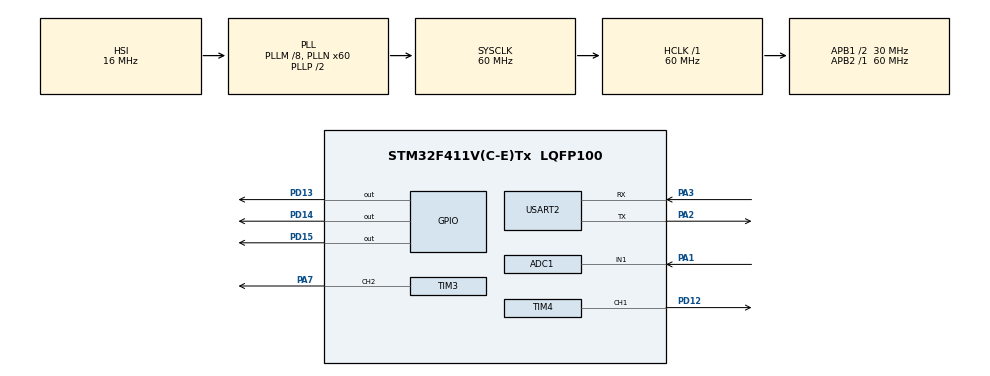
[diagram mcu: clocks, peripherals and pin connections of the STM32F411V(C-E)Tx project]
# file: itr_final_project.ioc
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ADC1.Channel-0\#ChannelRegularConversion=ADC_CHANNEL_1
ADC1.ExternalTrigConv=ADC_EXTERNALTRIGCONV_T2_TRGO
ADC1.NbrOfConversion=1
ADC1.NbrOfConversionFlag=1
ADC1.Rank-0\#ChannelRegularConversion=1
ADC1.SamplingTime-0\#ChannelRegularConversion=ADC_SAMPLETIME_480CYCLES
ADC1.master=1
Mcu.Family=STM32F4
Mcu.Name=STM32F411V(C-E)Tx
Mcu.Package=LQFP100
NVIC.ADC_IRQn=true\:0\:0\:false\:false\:true\:true\:true\:true
NVIC.PriorityGroup=NVIC_PRIORITYGROUP_4
NVIC.TIM3_IRQn=true\:0\:0\:false\:false\:true\:true\:true\:true
NVIC.USART2_IRQn=true\:0\:0\:false\:false\:true\:true\:true\:true
PA1.Signal=ADCx_IN1
PA13.Mode=Serial_Wire
PA13.Signal=SYS_JTMS-SWDIO
PA14.Mode=Serial_Wire
PA14.Signal=SYS_JTCK-SWCLK
PA2.Mode=Asynchronous
PA2.Signal=USART2_TX
PA3.Mode=Asynchronous
PA3.Signal=USART2_RX
PA7.Signal=S_TIM3_CH2
PD12.Signal=S_TIM4_CH1
PD13.Signal=GPIO_Output
PD14.Signal=GPIO_Output
PD15.Signal=GPIO_Output
PH0\ -\ OSC_IN.Mode=HSE-External-Oscillator
PH0\ -\ OSC_IN.Signal=RCC_OSC_IN
PH1\ -\ OSC_OUT.Mode=HSE-External-Oscillator
PH1\ -\ OSC_OUT.Signal=RCC_OSC_OUT
ProjectManager.HeapSize=0x200
ProjectManager.StackSize=0x400
ProjectManager.TargetToolchain=STM32CubeIDE
RCC.48MHZClocksFreq_Value=30000000
RCC.AHBFreq_Value=60000000
RCC.APB1CLKDivider=RCC_HCLK_DIV2
RCC.APB1Freq_Value=30000000
RCC.APB1TimFreq_Value=60000000
RCC.APB2Freq_Value=60000000
RCC.APB2TimFreq_Value=60000000
RCC.CortexFreq_Value=60000000
RCC.HCLKFreq_Value=60000000
RCC.HSE_VALUE=25000000
RCC.HSI_VALUE=16000000
RCC.LSE_VALUE=32768
RCC.PLLM=8
RCC.PLLN=60
RCC.SYSCLKFreq_VALUE=60000000
RCC.SYSCLKSource=RCC_SYSCLKSOURCE_PLLCLK
RCC.VCOOutputFreq_Value=120000000
SH.ADCx_IN1.0=ADC1_IN1,IN1
SH.S_TIM3_CH2.0=TIM3_CH2,PWM Generation2 CH2
SH.S_TIM4_CH1.0=TIM4_CH1,PWM Generation1 CH1
TIM2.Channel-PWM\ Generation1\ No\ Output=TIM_CHANNEL_1
TIM2.Period=119999
TIM2.TIM_MasterOutputTrigger=TIM_TRGO_UPDATE
TIM3.Channel-PWM\ Generation2\ CH2=TIM_CHANNEL_2
TIM3.Period=62499
TIM3.Prescaler=959
TIM3.Pulse-PWM\ Generation2\ CH2=31249
TIM4.Channel-PWM\ Generation1\ CH1=TIM_CHANNEL_1
TIM4.Period=999
TIM4.Prescaler=7
TIM4.Pulse-PWM\ Generation1\ CH1=499
USART2.VirtualMode=VM_ASYNC
VP_TIM2_VS_ClockSourceINT.Mode=Internal
VP_TIM2_VS_no_output1.Mode=PWM Generation1 No Output
VP_TIM3_VS_ClockSourceINT.Mode=Internal
VP_TIM4_VS_ClockSourceINT.Mode=Internal
board=custom

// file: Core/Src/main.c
/* USER CODE BEGIN Header */
/**
 ******************************************************************************
 * @file           : main.c
 * @brief          : Main program body
 ******************************************************************************
 * @attention
 *
 * Copyright (c) 2024 STMicroelectronics.
 * All rights reserved.
 *
 * This software is licensed under terms that can be found in the LICENSE file
 * in the root directory of this software component.
 * If no LICENSE file comes with this software, it is provided AS-IS.
 *
 ******************************************************************************
 */
/* USER CODE END Header */
#include "main.h"

/* USER CODE BEGIN Includes */
#include "sys_buzz.h"
#include "sys_led.h"
#include "sys_mng.h"
#include "sys_uart.h"

/* USER CODE END Includes */

ADC_HandleTypeDef hadc1;

TIM_HandleTypeDef htim2;
TIM_HandleTypeDef htim3;
TIM_HandleTypeDef htim4;

UART_HandleTypeDef huart2;

void        SystemClock_Config(void);
static void MX_GPIO_Init(void);
static void MX_TIM3_Init(void);
static void MX_TIM4_Init(void);
static void MX_ADC1_Init(void);
static void MX_TIM2_Init(void);
static void MX_USART2_UART_Init(void);

int main(void)
{

  /* MCU Configuration--------------------------------------------------------*/

  /* Reset of all peripherals, Initializes the Flash interface and the Systick. */
  HAL_Init();

  /* Configure the system clock */
  SystemClock_Config();

  /* Initialize all configured peripherals */
  MX_GPIO_Init();
  MX_TIM3_Init();
  MX_TIM4_Init();
  MX_ADC1_Init();
  MX_TIM2_Init();
  MX_USART2_UART_Init();
  /* USER CODE BEGIN 2 */
  sys_mng_init(&hadc1, &htim2, TIM_CHANNEL_1);
  sys_uart_init(&huart2);
  sys_led_init(&htim3);
  sys_buzzer_init(&htim4, GPIOD, GPIO_PIN_15);

  /* USER CODE END 2 */

  /* Infinite loop */
  /* USER CODE BEGIN WHILE */
  while (1)
  {
    sys_uart_loop();
    sys_mng_loop();
    sys_buzzer_loop();
    sys_led_loop();
    /* USER CODE END WHILE */

  }
}

void SystemClock_Config(void)
{
  RCC_OscInitTypeDef RCC_OscInitStruct = { 0 };
  RCC_ClkInitTypeDef RCC_ClkInitStruct = { 0 };

  /** Configure the main internal regulator output voltage
   */
  __HAL_RCC_PWR_CLK_ENABLE();
  __HAL_PWR_VOLTAGESCALING_CONFIG(PWR_REGULATOR_VOLTAGE_SCALE1);

  /** Initializes the RCC Oscillators according to the specified parameters
   * in the RCC_OscInitTypeDef structure.
   */
  RCC_OscInitStruct.OscillatorType      = RCC_OSCILLATORTYPE_HSI;
  RCC_OscInitStruct.HSIState            = RCC_HSI_ON;
  RCC_OscInitStruct.HSICalibrationValue = RCC_HSICALIBRATION_DEFAULT;
  RCC_OscInitStruct.PLL.PLLState        = RCC_PLL_ON;
  RCC_OscInitStruct.PLL.PLLSource       = RCC_PLLSOURCE_HSI;
  RCC_OscInitStruct.PLL.PLLM            = 8;
  RCC_OscInitStruct.PLL.PLLN            = 60;
  RCC_OscInitStruct.PLL.PLLP            = RCC_PLLP_DIV2;
  RCC_OscInitStruct.PLL.PLLQ            = 4;
  if (HAL_RCC_OscConfig(&RCC_OscInitStruct) != HAL_OK)
  {
    Error_Handler();
  }

  /** Initializes the CPU, AHB and APB buses clocks
   */
  RCC_ClkInitStruct.ClockType = RCC_CLOCKTYPE_HCLK | RCC_CLOCKTYPE_SYSCLK |
  RCC_CLOCKTYPE_PCLK1 | RCC_CLOCKTYPE_PCLK2;
  RCC_ClkInitStruct.SYSCLKSource   = RCC_SYSCLKSOURCE_PLLCLK;
  RCC_ClkInitStruct.AHBCLKDivider  = RCC_SYSCLK_DIV1;
  RCC_ClkInitStruct.APB1CLKDivider = RCC_HCLK_DIV2;
  RCC_ClkInitStruct.APB2CLKDivider = RCC_HCLK_DIV1;

  if (HAL_RCC_ClockConfig(&RCC_ClkInitStruct, FLASH_LATENCY_1) != HAL_OK)
  {
    Error_Handler();
  }
}

static void MX_ADC1_Init(void)
{

  ADC_ChannelConfTypeDef sConfig = { 0 };

  /** Configure the global features of the ADC (Clock, Resolution, Data Alignment and number of conversion)
   */
  hadc1.Instance                   = ADC1;
  hadc1.Init.ClockPrescaler        = ADC_CLOCK_SYNC_PCLK_DIV2;
  hadc1.Init.Resolution            = ADC_RESOLUTION_12B;
  hadc1.Init.ScanConvMode          = DISABLE;
  hadc1.Init.ContinuousConvMode    = DISABLE;
  hadc1.Init.DiscontinuousConvMode = DISABLE;
  hadc1.Init.ExternalTrigConvEdge  = ADC_EXTERNALTRIGCONVEDGE_RISING;
  hadc1.Init.ExternalTrigConv      = ADC_EXTERNALTRIGCONV_T2_TRGO;
  hadc1.Init.DataAlign             = ADC_DATAALIGN_RIGHT;
  hadc1.Init.NbrOfConversion       = 1;
  hadc1.Init.DMAContinuousRequests = DISABLE;
  hadc1.Init.EOCSelection          = ADC_EOC_SINGLE_CONV;
  if (HAL_ADC_Init(&hadc1) != HAL_OK)
  {
    Error_Handler();
  }

  /** Configure for the selected ADC regular channel its corresponding rank in the sequencer and its sample time.
   */
  sConfig.Channel      = ADC_CHANNEL_1;
  sConfig.Rank         = 1;
  sConfig.SamplingTime = ADC_SAMPLETIME_480CYCLES;
  if (HAL_ADC_ConfigChannel(&hadc1, &sConfig) != HAL_OK)
  {
    Error_Handler();
  }
}

static void MX_TIM2_Init(void)
{

  TIM_ClockConfigTypeDef  sClockSourceConfig = { 0 };
  TIM_MasterConfigTypeDef sMasterConfig      = { 0 };
  TIM_OC_InitTypeDef      sConfigOC          = { 0 };

  htim2.Instance               = TIM2;
  htim2.Init.Prescaler         = 0;
  htim2.Init.CounterMode       = TIM_COUNTERMODE_UP;
  htim2.Init.Period            = 119999;
  htim2.Init.ClockDivision     = TIM_CLOCKDIVISION_DIV1;
  htim2.Init.AutoReloadPreload = TIM_AUTORELOAD_PRELOAD_DISABLE;
  if (HAL_TIM_Base_Init(&htim2) != HAL_OK)
  {
    Error_Handler();
  }
  sClockSourceConfig.ClockSource = TIM_CLOCKSOURCE_INTERNAL;
  if (HAL_TIM_ConfigClockSource(&htim2, &sClockSourceConfig) != HAL_OK)
  {
    Error_Handler();
  }
  if (HAL_TIM_PWM_Init(&htim2) != HAL_OK)
  {
    Error_Handler();
  }
  sMasterConfig.MasterOutputTrigger = TIM_TRGO_UPDATE;
  sMasterConfig.MasterSlaveMode     = TIM_MASTERSLAVEMODE_DISABLE;
  if (HAL_TIMEx_MasterConfigSynchronization(&htim2, &sMasterConfig) != HAL_OK)
  {
    Error_Handler();
  }
  sConfigOC.OCMode     = TIM_OCMODE_PWM1;
  sConfigOC.Pulse      = 0;
  sConfigOC.OCPolarity = TIM_OCPOLARITY_HIGH;
  sConfigOC.OCFastMode = TIM_OCFAST_DISABLE;
  if (HAL_TIM_PWM_ConfigChannel(&htim2, &sConfigOC, TIM_CHANNEL_1) != HAL_OK)
  {
    Error_Handler();
  }
}

static void MX_TIM3_Init(void)
{

  TIM_ClockConfigTypeDef  sClockSourceConfig = { 0 };
  TIM_MasterConfigTypeDef sMasterConfig      = { 0 };
  TIM_OC_InitTypeDef      sConfigOC          = { 0 };

  htim3.Instance               = TIM3;
  htim3.Init.Prescaler         = 959;
  htim3.Init.CounterMode       = TIM_COUNTERMODE_UP;
  htim3.Init.Period            = 62499;
  htim3.Init.ClockDivision     = TIM_CLOCKDIVISION_DIV1;
  htim3.Init.AutoReloadPreload = TIM_AUTORELOAD_PRELOAD_DISABLE;
  if (HAL_TIM_Base_Init(&htim3) != HAL_OK)
  {
    Error_Handler();
  }
  sClockSourceConfig.ClockSource = TIM_CLOCKSOURCE_INTERNAL;
  if (HAL_TIM_ConfigClockSource(&htim3, &sClockSourceConfig) != HAL_OK)
  {
    Error_Handler();
  }
  if (HAL_TIM_PWM_Init(&htim3) != HAL_OK)
  {
    Error_Handler();
  }
  sMasterConfig.MasterOutputTrigger = TIM_TRGO_RESET;
  sMasterConfig.MasterSlaveMode     = TIM_MASTERSLAVEMODE_DISABLE;
  if (HAL_TIMEx_MasterConfigSynchronization(&htim3, &sMasterConfig) != HAL_OK)
  {
    Error_Handler();
  }
  sConfigOC.OCMode     = TIM_OCMODE_PWM1;
  sConfigOC.Pulse      = 31249;
  sConfigOC.OCPolarity = TIM_OCPOLARITY_HIGH;
  sConfigOC.OCFastMode = TIM_OCFAST_DISABLE;
  if (HAL_TIM_PWM_ConfigChannel(&htim3, &sConfigOC, TIM_CHANNEL_2) != HAL_OK)
  {
    Error_Handler();
  }
  HAL_TIM_MspPostInit(&htim3);
}

static void MX_TIM4_Init(void)
{

  TIM_ClockConfigTypeDef  sClockSourceConfig = { 0 };
  TIM_MasterConfigTypeDef sMasterConfig      = { 0 };
  TIM_OC_InitTypeDef      sConfigOC          = { 0 };

  htim4.Instance               = TIM4;
  htim4.Init.Prescaler         = 7;
  htim4.Init.CounterMode       = TIM_COUNTERMODE_UP;
  htim4.Init.Period            = 999;
  htim4.Init.ClockDivision     = TIM_CLOCKDIVISION_DIV1;
  htim4.Init.AutoReloadPreload = TIM_AUTORELOAD_PRELOAD_DISABLE;
  if (HAL_TIM_Base_Init(&htim4) != HAL_OK)
  {
    Error_Handler();
  }
  sClockSourceConfig.ClockSource = TIM_CLOCKSOURCE_INTERNAL;
  if (HAL_TIM_ConfigClockSource(&htim4, &sClockSourceConfig) != HAL_OK)
  {
    Error_Handler();
  }
  if (HAL_TIM_PWM_Init(&htim4) != HAL_OK)
  {
    Error_Handler();
  }
  sMasterConfig.MasterOutputTrigger = TIM_TRGO_RESET;
  sMasterConfig.MasterSlaveMode     = TIM_MASTERSLAVEMODE_DISABLE;
  if (HAL_TIMEx_MasterConfigSynchronization(&htim4, &sMasterConfig) != HAL_OK)
  {
    Error_Handler();
  }
  sConfigOC.OCMode     = TIM_OCMODE_PWM1;
  sConfigOC.Pulse      = 499;
  sConfigOC.OCPolarity = TIM_OCPOLARITY_HIGH;
  sConfigOC.OCFastMode = TIM_OCFAST_DISABLE;
  if (HAL_TIM_PWM_ConfigChannel(&htim4, &sConfigOC, TIM_CHANNEL_1) != HAL_OK)
  {
    Error_Handler();
  }
  HAL_TIM_MspPostInit(&htim4);
}

static void MX_USART2_UART_Init(void)
{

  huart2.Instance          = USART2;
  huart2.Init.BaudRate     = 115200;
  huart2.Init.WordLength   = UART_WORDLENGTH_8B;
  huart2.Init.StopBits     = UART_STOPBITS_1;
  huart2.Init.Parity       = UART_PARITY_NONE;
  huart2.Init.Mode         = UART_MODE_TX_RX;
  huart2.Init.HwFlowCtl    = UART_HWCONTROL_NONE;
  huart2.Init.OverSampling = UART_OVERSAMPLING_16;
  if (HAL_UART_Init(&huart2) != HAL_OK)
  {
    Error_Handler();
  }
}

static void MX_GPIO_Init(void)
{
  GPIO_InitTypeDef GPIO_InitStruct = { 0 };

  /* GPIO Ports Clock Enable */
  __HAL_RCC_GPIOH_CLK_ENABLE();
  __HAL_RCC_GPIOA_CLK_ENABLE();
  __HAL_RCC_GPIOD_CLK_ENABLE();

  /*Configure GPIO pin Output Level */
  HAL_GPIO_WritePin(GPIOD, GPIO_PIN_13 | GPIO_PIN_14 | GPIO_PIN_15, GPIO_PIN_RESET);

  /*Configure GPIO pins : PD13 PD14 PD15 */
  GPIO_InitStruct.Pin   = GPIO_PIN_13 | GPIO_PIN_14 | GPIO_PIN_15;
  GPIO_InitStruct.Mode  = GPIO_MODE_OUTPUT_PP;
  GPIO_InitStruct.Pull  = GPIO_NOPULL;
  GPIO_InitStruct.Speed = GPIO_SPEED_FREQ_LOW;
  HAL_GPIO_Init(GPIOD, &GPIO_InitStruct);

}

void Error_Handler(void)
{
  __disable_irq();
  while (1)
  {
  }
}
